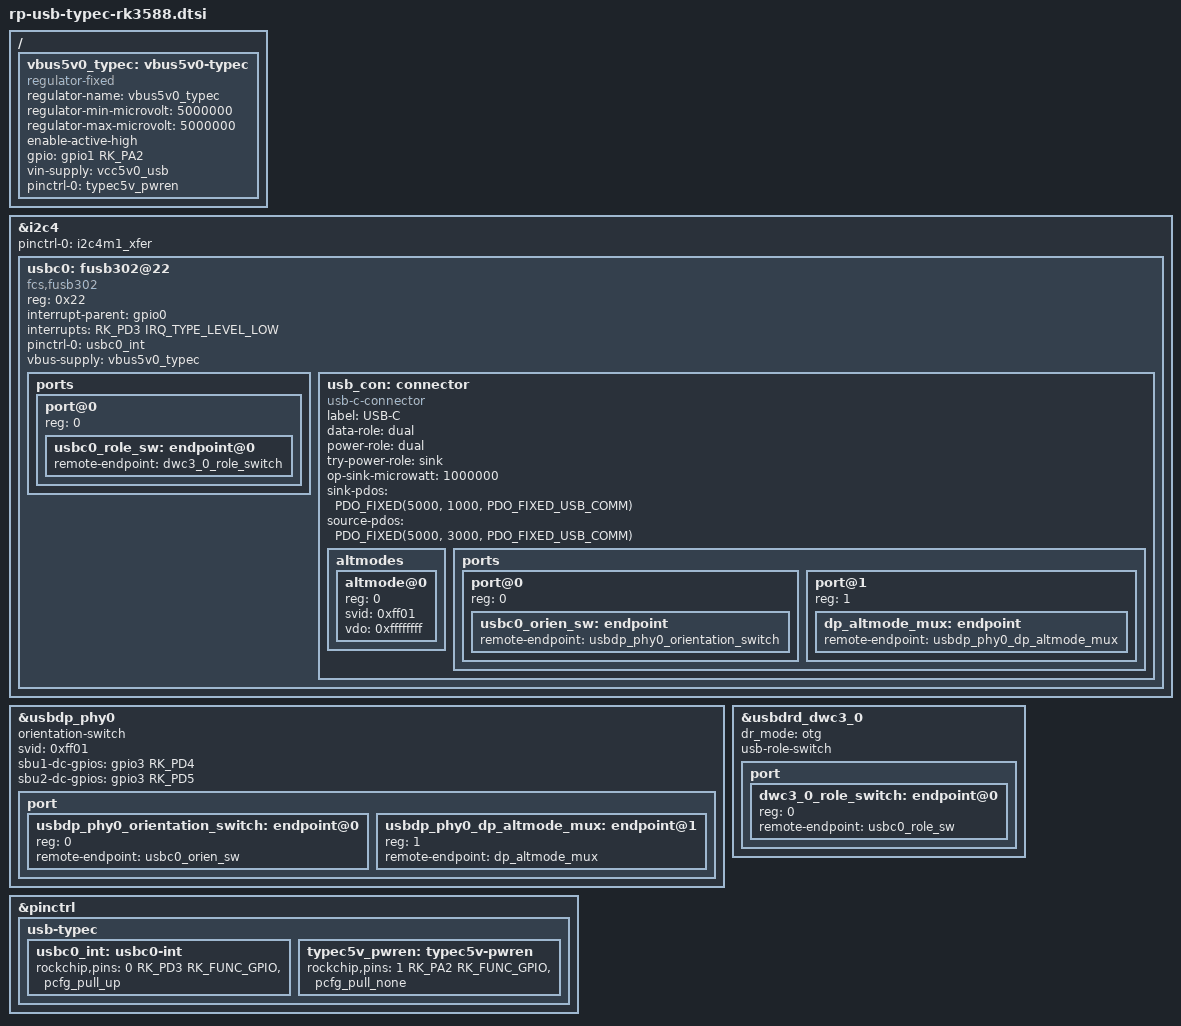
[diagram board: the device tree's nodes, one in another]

/ {
        vbus5v0_typec: vbus5v0-typec {
                compatible = "regulator-fixed";
                regulator-name = "vbus5v0_typec";
                regulator-min-microvolt = <5000000>;
                regulator-max-microvolt = <5000000>;
                enable-active-high;
                gpio = <&gpio1 RK_PA2 GPIO_ACTIVE_HIGH>;
                vin-supply = <&vcc5v0_usb>;
                pinctrl-names = "default";
                pinctrl-0 = <&typec5v_pwren>;
        };
};



&i2c4 {
    status = "okay";
    pinctrl-names = "default";
    pinctrl-0 = <&i2c4m1_xfer>;

    usbc0: fusb302@22 {
        compatible = "fcs,fusb302";
        reg = <0x22>;
        interrupt-parent = <&gpio0>;
        interrupts = <RK_PD3 IRQ_TYPE_LEVEL_LOW>;
        pinctrl-names = "default";
        pinctrl-0 = <&usbc0_int>;
        vbus-supply = <&vbus5v0_typec>;
        status = "okay";

        ports {
            #address-cells = <1>;
            #size-cells = <0>;

            port@0 {
                reg = <0>;
                usbc0_role_sw: endpoint@0 {
                    remote-endpoint = <&dwc3_0_role_switch>;
                };
            };
        };

        usb_con: connector {
            compatible = "usb-c-connector";
            label = "USB-C";
            data-role = "dual";
            power-role = "dual";
            try-power-role = "sink";
            op-sink-microwatt = <1000000>;
            sink-pdos =
                <PDO_FIXED(5000, 1000, PDO_FIXED_USB_COMM)>;
            source-pdos =
                <PDO_FIXED(5000, 3000, PDO_FIXED_USB_COMM)>;

            altmodes {
                #address-cells = <1>;
                #size-cells = <0>;

                altmode@0 {
                    reg = <0>;
                    svid = <0xff01>;
                    vdo = <0xffffffff>;
                };
            };

            ports {
                #address-cells = <1>;
                #size-cells = <0>;

                port@0 {
                    reg = <0>;
                    usbc0_orien_sw: endpoint {
                        remote-endpoint = <&usbdp_phy0_orientation_switch>;
                    };
                };

                port@1 {
                    reg = <1>;
                    dp_altmode_mux: endpoint {
                        remote-endpoint = <&usbdp_phy0_dp_altmode_mux>;
                    };
                };
            };
        };
    };
};


&usbdp_phy0 {
    orientation-switch;
    svid = <0xff01>;
    sbu1-dc-gpios = <&gpio3 RK_PD4 GPIO_ACTIVE_HIGH>;
    sbu2-dc-gpios = <&gpio3 RK_PD5 GPIO_ACTIVE_HIGH>;

    port {
        #address-cells = <1>;
        #size-cells = <0>;
        usbdp_phy0_orientation_switch: endpoint@0 {
            reg = <0>;
            remote-endpoint = <&usbc0_orien_sw>;
        };

        usbdp_phy0_dp_altmode_mux: endpoint@1 {
            reg = <1>;
            remote-endpoint = <&dp_altmode_mux>;
        };
    };
};


&usbdrd_dwc3_0 {
    dr_mode = "otg";
    usb-role-switch;
    port {
        #address-cells = <1>;
        #size-cells = <0>;
        dwc3_0_role_switch: endpoint@0 {
            reg = <0>;
            remote-endpoint = <&usbc0_role_sw>;
        };
    };
};

&pinctrl {
        usb-typec {
                usbc0_int: usbc0-int {
                        rockchip,pins = <0 RK_PD3 RK_FUNC_GPIO &pcfg_pull_up>;
                };

                typec5v_pwren: typec5v-pwren {
                        rockchip,pins = <1 RK_PA2 RK_FUNC_GPIO &pcfg_pull_none>;
                };
 
       };
};
